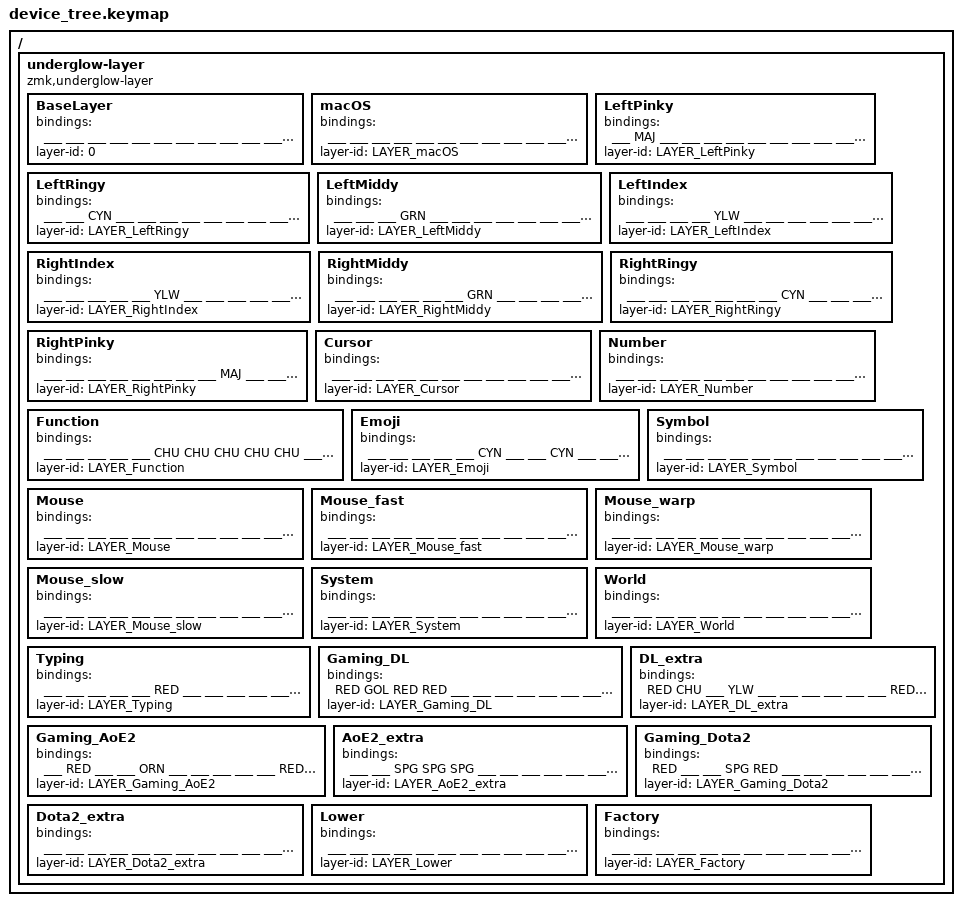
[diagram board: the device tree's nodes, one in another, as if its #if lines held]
//////////////////////////////////////////////////////////////////////////////
//
// Per-key RGB indicators for layers & mods -- requires PR36 beta firmware:
// override "EXPERIMENTAL_RGB_LAYER" to "y" in Advanced Configuration and
// select "community.pr36.per-key-rgb" from the drop-down menu located at
// Glove80 Layout Editor > Settings > Advanced Settings > Firmware Version
//
// - https://github.com/moergo-sc/zmk/pull/36
// - https://github.com/moergo-sc/zmk/pull/30
// - https://github.com/zmkfirmware/zmk/pull/2752
// - https://dev.glove80.com/#/layout/user/c42ac32d-dc0d-4160-9ee3-fd0fc15f1725
//
//////////////////////////////////////////////////////////////////////////////

#if __has_include(<dt-bindings/zmk/rgb_colors.h>)
  //
  // Color definitions with conflict guard to prevent
  // accidental redefinition of common abbreviations.
  //
  #if defined(RED) || defined(RED_RGB) || \
      defined(DOR) || defined(DOR_RGB) || \
      defined(COR) || defined(COR_RGB) || \
      defined(ORN) || defined(ORN_RGB) || \
      defined(GDN) || defined(GDN_RGB) || \
      defined(GOL) || defined(GOL_RGB) || \
      defined(YLW) || defined(YLW_RGB) || \
      defined(CHU) || defined(CHU_RGB) || \
      defined(GRN) || defined(GRN_RGB) || \
      defined(SPG) || defined(SPG_RGB) || \
      defined(CYN) || defined(CYN_RGB) || \
      defined(AZU) || defined(AZU_RGB) || \
      defined(TEA) || defined(TEA_RGB) || \
      defined(TUR) || defined(TUR_RGB) || \
      defined(BLU) || defined(BLU_RGB) || \
      defined(PUR) || defined(PUR_RGB) || \
      defined(MAJ) || defined(MAJ_RGB) || \
      defined(PNK) || defined(PNK_RGB) || \
      defined(WHT) || defined(WHT_RGB) || \
      defined(BLK) || defined(BLK_RGB) || \
      defined(___) || \
      defined(DUG) || defined(DUG_RGB) || \
      defined(LAC) || defined(LAC_RGB) || \
      defined(BSL) || defined(BNL) || defined(BCL) || \
      defined(SSL) || defined(SNL) || defined(SCL) || \
      defined(FST) || defined(WRP) || defined(SLO)
  #error "Naming conflict: 3-letter color abbreviation already defined!"
  #endif

  //
  // color definitions from QMK
  // https://github.com/qmk/qmk_firmware/blob/master/quantum/color.h
  //

  // used for delete & other possibly very destructive keys
  // also used to indicate which layer is currently active
  #define RED_RGB 0xFF0000 // #FF0000 RED      => RED (red)

  // used for keys that are not AS destructive, but whose function is to close/quit things.
  // also used for the escape characters `\` and ```
  #define DOR_RGB 0xFF4500 // #FF4500 DARKORN  => DOR (dark ornj)

  // used for basic, all rounder punctuations such as `;,.'"%:@`
  #define COR_RGB 0xFF7C4D // #FF7C4D CORAL    => COR (coral)

  // used for number keys
  // also used for ^$ vim start/end of line keys and for home/end
  #define ORN_RGB 0xFF8000 // #FF8000 ORANGE   => ORN (ornj)

  // used for /*+- and such keys that can represent some sort of "operation"
  #define GDN_RGB 0xD9A521 // #D9A521 GOLDNROD => GDN (gold'nrod)

  // used for !~#? keys, meant to often be combined with other symbols, their functionality
  // often ressembles that of the GDN_RGB keys: thus, so does their color.
  #define GOL_RGB 0xFFD900 // #FFD900 GOLD     => GOL (gold)

  // SHIFT HRM.
  // also used for sticky shift keys
  #define YLW_RGB 0xFFFF00 // #FFFF00 YELLOW   => YLW (yellow)

  //
  #define CHU_RGB 0x80FF00 // #80FF00 CHARTRSE => CHU (chartreuse)

  // CTRL HRM.
  #define GRN_RGB 0x00FF00 // #00FF00 GREEN    => GRN (green)

  //
  #define SPG_RGB 0x00FF80 // #00FF80 SPRINGRN => SPG (spring green)

  // ALT/OPT OS HMR.
  #define CYN_RGB 0x00FFFF // #00FFFF CYAN     => CYN (sigh-an)

  // used for simple keys that do not do much on their own, such as an ArrowKey,
  // a Mouse Direction key, or a simple letter, sometimes capitalized.
  #define AZU_RGB 0x99F5FF // #99F5FF AZURE    => AZU (a-zur)

  // sligth variation of AZU_RGB, for very similar keys
  #define TUR_RGB 0x476E6A // #476E6A TURQUOIS => TUR (turquoise)

  // used for "containers" keys: (), [], {}, <>
  #define TEA_RGB 0x008080 // #008080 TEAL     => TEA (teel)

  // used only for a few programming fundamental keys such as `_`, `|` and `&`
  #define BLU_RGB 0x0000FF // #0000FF BLUE     => BLU (bloo)

  // used for combo keys (undo, redo, <c-f> find), not quite real macros yet
  #define PUR_RGB 0x7A00FF // #7A00FF PURPLE   => PUR (purp)

  // OS KEY HRM.
  #define MAJ_RGB 0xFF00FF // #FF00FF MAGENTA  => MAJ (mah-jenta)

  // used for the `=` key
  #define PNK_RGB 0xFF80BF // #FF80BF PINK     => PNK (pink)

  // used for macro keys
  #define WHT_RGB 0xFFFFFF // #FFFFFF WHITE    => WHT (white)

  // no RBG lighting. Used for keys that shoud not require a particular effort remembering —
  // mostly, alpha layout keys
  #define BLK_RGB 0x000000 // #000000 BLACK    => BLK (blak)

  //
  // color definitions from MoErgo
  // https://github.com/moergo-sc/zmk/blob/aca523dfce9b6447ffd19d833b791d44f1f286de/app/src/rgb_underglow.c#L259-L265
  //
  #define DUG_RGB 0x00ff68 // #00ff68 DULL_GRN => DUG (dull green)

  // used for layer switching keys.
  // also used for the Space, Backspace, Tab and Enter keys on temporary layers
  #define LAC_RGB 0x6b1fce // #6b1fce LILAC    => LAC (lilac)

  //
  // underglow for the colors above
  //
  #define RED &ug RED_RGB
  #define DOR &ug DOR_RGB
  #define COR &ug COR_RGB
  #define ORN &ug ORN_RGB
  #define GDN &ug GDN_RGB
  #define GOL &ug GOL_RGB
  #define YLW &ug YLW_RGB
  #define CHU &ug CHU_RGB
  #define GRN &ug GRN_RGB
  #define SPG &ug SPG_RGB
  #define CYN &ug CYN_RGB
  #define AZU &ug AZU_RGB
  #define TEA &ug TEA_RGB
  #define TUR &ug TUR_RGB
  #define BLU &ug BLU_RGB
  #define PUR &ug PUR_RGB
  #define MAJ &ug MAJ_RGB
  #define PNK &ug PNK_RGB
  #define WHT &ug WHT_RGB
  #define BLK &ug BLK_RGB
  #define ___ &ug BLK_RGB
  #define DUG &ug DUG_RGB
  #define LAC &ug LAC_RGB

  //
  // underglow for keyboard locks on the Base layer
  //
  #define BSL &ug_sl BLK_RGB WHT_RGB // ScrollLock COLOR_OFF COLOR_ON
  #define BNL &ug_nl LAC_RGB WHT_RGB // NumLock    COLOR_OFF COLOR_ON
  #define BCL &ug_cl LAC_RGB WHT_RGB // CapsLock   COLOR_OFF COLOR_ON

  //
  // underglow for keyboard locks on the System layer
  //
  #define SSL &ug_sl BLK_RGB WHT_RGB // ScrollLock COLOR_OFF COLOR_ON
  #define SNL &ug_nl BLK_RGB WHT_RGB // NumLock    COLOR_OFF COLOR_ON
  #define SCL &ug_cl BLK_RGB WHT_RGB // CapsLock   COLOR_OFF COLOR_ON

  //
  // colors for mouse speed scaling in Mouse layers
  //
  #define FST GOL
  #define SLO PNK
  #define WRP CHU

  // ==== PER-KEY-RGB <section begins> ====
  / {
    underglow-layer {
      compatible  = "zmk,underglow-layer";

      /*
      Template {
        bindings = <
          ___ ___ ___ ___ ___                                             ___ ___ ___ ___ ___
          ___ ___ ___ ___ ___ ___                                     ___ ___ ___ ___ ___ ___
          ___ ___ ___ ___ ___ ___                                     ___ ___ ___ ___ ___ ___
          ___ ___ ___ ___ ___ ___                                     ___ ___ ___ ___ ___ ___
          ___ ___ ___ ___ ___ ___     ___ ___ ___     ___ ___ ___     ___ ___ ___ ___ ___ ___
          ___ ___ ___ ___ ___         ___ ___ ___     ___ ___ ___         ___ ___ ___ ___ ___
        >;
        layer-id = <LAYER_Template>;
      };
      */

      BaseLayer {
        bindings = <
          ___ ___ ___ ___ ___                                             ___ ___ ___ ___ ___
          ___ ___ ___ ___ ___ ___                                     ___ ___ ___ ___ ___ ___
          ___ ___ ___ ___ ___ ___                                     ___ ___ ___ ___ ___ ___
          ___ MAJ CYN GRN YLW ___                                     ___ YLW GRN CYN MAJ ___
          YLW ___ ___ ___ ___ ___     LAC ___ ___     ___ ___ LAC     ___ ___ ___ ___ ___ YLW
          RED ___ ___ ___ LAC         BCL BNL BSL     ___ LAC LAC         LAC ___ ___ ___ ___
        >;
        layer-id = <0>;
      };

      #ifdef LAYER_macOS
      macOS {
        bindings = <
          ___ ___ ___ ___ ___                                             ___ ___ ___ ___ ___
          ___ ___ ___ ___ ___ ___                                     ___ ___ ___ ___ ___ ___
          ___ ___ ___ ___ ___ ___                                     ___ ___ ___ ___ ___ ___
          ___ GRN CYN MAJ YLW ___                                     ___ YLW MAJ CYN GRN ___
          YLW ___ ___ ___ ___ ___     LAC RED ___     ___ ___ LAC     ___ ___ ___ ___ ___ YLW
          RED RED ___ ___ LAC         BCL BNL BSL     ___ LAC LAC         LAC ___ ___ RED RED
        >;
        layer-id = <LAYER_macOS>;
      };
      #endif

      #ifdef LAYER_LeftPinky
      LeftPinky {
        bindings = <
          ___ MAJ ___ ___ ___                                             ___ ___ ___ ___ ___
          ___ ___ ___ ___ ___ ___                                     ___ ___ ___ ___ ___ ___
          ___ ___ ___ ___ ___ ___                                     ___ ___ ___ ___ ___ ___
          ___ MAJ CYN GRN YLW ___                                     ___ YLW GRN CYN MAJ ___
          YLW ___ ___ ___ ___ ___     LAC COR ___     ___ COR LAC     ___ ___ ___ ___ ___ YLW
          ___ ___ ___ ___ LAC         BCL BNL BSL     ___ LAC LAC         LAC ___ ___ ___ ___
        >;
        layer-id = <LAYER_LeftPinky>;
      };
      #endif

      #ifdef LAYER_LeftRingy
      LeftRingy {
        bindings = <
          ___ ___ CYN ___ ___                                             ___ ___ ___ ___ ___
          ___ ___ ___ ___ ___ ___                                     ___ ___ ___ ___ ___ ___
          ___ ___ ___ ___ ___ ___                                     ___ ___ ___ ___ ___ ___
          ___ MAJ CYN GRN YLW ___                                     ___ YLW GRN CYN MAJ ___
          YLW ___ ___ ___ ___ ___     LAC COR ___     ___ COR LAC     ___ ___ ___ ___ ___ YLW
          ___ ___ ___ ___ LAC         BCL BNL BSL     ___ LAC LAC         LAC ___ ___ ___ ___
        >;
        layer-id = <LAYER_LeftRingy>;
      };
      #endif

      #ifdef LAYER_LeftMiddy
      LeftMiddy {
        bindings = <
          ___ ___ ___ GRN ___                                             ___ ___ ___ ___ ___
          ___ ___ ___ ___ ___ ___                                     ___ ___ ___ ___ ___ ___
          ___ ___ ___ ___ ___ ___                                     ___ ___ ___ ___ ___ ___
          ___ MAJ CYN GRN YLW ___                                     ___ YLW GRN CYN MAJ ___
          YLW ___ ___ ___ ___ ___     LAC COR ___     ___ COR LAC     ___ ___ ___ ___ ___ YLW
          ___ ___ ___ ___ LAC         BCL BNL BSL     ___ LAC LAC         LAC ___ ___ ___ ___
        >;
        layer-id = <LAYER_LeftMiddy>;
      };
      #endif

      #ifdef LAYER_LeftIndex
      LeftIndex {
        bindings = <
          ___ ___ ___ ___ YLW                                             ___ ___ ___ ___ ___
          ___ ___ ___ ___ ___ ___                                     ___ ___ ___ ___ ___ ___
          ___ ___ ___ ___ ___ ___                                     ___ ___ ___ ___ ___ ___
          ___ MAJ CYN GRN YLW ___                                     ___ YLW GRN CYN MAJ ___
          YLW ___ ___ ___ ___ ___     LAC COR ___     ___ COR LAC     ___ ___ ___ ___ ___ YLW
          ___ ___ ___ ___ LAC         BCL BNL BSL     ___ LAC LAC         LAC ___ ___ ___ ___
        >;
        layer-id = <LAYER_LeftIndex>;
      };
      #endif

      #ifdef LAYER_RightIndex
      RightIndex {
        bindings = <
          ___ ___ ___ ___ ___                                             YLW ___ ___ ___ ___
          ___ ___ ___ ___ ___ ___                                     ___ ___ ___ ___ ___ ___
          ___ ___ ___ ___ ___ ___                                     ___ ___ ___ ___ ___ ___
          ___ MAJ CYN GRN YLW ___                                     ___ YLW GRN CYN MAJ ___
          YLW ___ ___ ___ ___ ___     LAC COR ___     ___ COR LAC     ___ ___ ___ ___ ___ YLW
          ___ ___ ___ ___ LAC         BCL BNL BSL     ___ LAC LAC         LAC ___ ___ ___ ___
        >;
        layer-id = <LAYER_RightIndex>;
      };
      #endif

      #ifdef LAYER_RightMiddy
      RightMiddy {
        bindings = <
          ___ ___ ___ ___ ___                                             ___ GRN ___ ___ ___
          ___ ___ ___ ___ ___ ___                                     ___ ___ ___ ___ ___ ___
          ___ ___ ___ ___ ___ ___                                     ___ ___ ___ ___ ___ ___
          ___ MAJ CYN GRN YLW ___                                     ___ YLW GRN CYN MAJ ___
          YLW ___ ___ ___ ___ ___     LAC COR ___     ___ COR LAC     ___ ___ ___ ___ ___ YLW
          ___ ___ ___ ___ LAC         BCL BNL BSL     ___ LAC LAC         LAC ___ ___ ___ ___
        >;
        layer-id = <LAYER_RightMiddy>;
      };
      #endif

      #ifdef LAYER_RightRingy
      RightRingy {
        bindings = <
          ___ ___ ___ ___ ___                                             ___ ___ CYN ___ ___
          ___ ___ ___ ___ ___ ___                                     ___ ___ ___ ___ ___ ___
          ___ ___ ___ ___ ___ ___                                     ___ ___ ___ ___ ___ ___
          ___ MAJ CYN GRN YLW ___                                     ___ YLW GRN CYN MAJ ___
          YLW ___ ___ ___ ___ ___     LAC COR ___     ___ COR LAC     ___ ___ ___ ___ ___ YLW
          ___ ___ ___ ___ LAC         BCL BNL BSL     ___ LAC LAC         LAC ___ ___ ___ ___
        >;
        layer-id = <LAYER_RightRingy>;
      };
      #endif

      #ifdef LAYER_RightPinky
      RightPinky {
        bindings = <
          ___ ___ ___ ___ ___                                             ___ ___ ___ MAJ ___
          ___ ___ ___ ___ ___ ___                                     ___ ___ ___ ___ ___ ___
          ___ ___ ___ ___ ___ ___                                     ___ ___ ___ ___ ___ ___
          ___ MAJ CYN GRN YLW ___                                     ___ YLW GRN CYN MAJ ___
          YLW ___ ___ ___ ___ ___     LAC COR ___     ___ COR LAC     ___ ___ ___ ___ ___ YLW
          ___ ___ ___ ___ LAC         BCL BNL BSL     ___ LAC LAC         LAC ___ ___ ___ ___
        >;
        layer-id = <LAYER_RightPinky>;
      };
      #endif

      #ifdef LAYER_Cursor
      Cursor {
        bindings = <
          ___ ___ ___ ___ ___                                             ___ ___ ___ ___ ___
          ___ ___ ___ ___ ___ ___                                     ___ ___ ___ ___ ___ ___
          ___ ___ WHT WHT WHT GDN                                     ___ ___ COR COR DOR ___
          WHT MAJ CYN GRN YLW GDN                                     BLU AZU AZU AZU AZU ___
          WHT RED PUR PUR GDN GDN     ___ ___ ___     WHT WHT WHT     BLU ORN PUR PUR ORN ___
          WHT PNK PUR PUR PUR         RED ___ ___     WHT WHT WHT         ___ COR COR PNK ___
        >;
        layer-id = <LAYER_Cursor>;
      };
      #endif

      #ifdef LAYER_Number
      Number {
        bindings = <
          ___ ___ ___ ___ ___                                             ___ ___ ___ ___ ___
          ___ ___ ___ ___ ___ ___                                     ___ ___ ___ ___ ___ ___
          ___ PNK PNK PNK PNK PNK                                     TUR ORN ORN ORN BLU ___
          ___ MAJ CYN GRN YLW PNK                                     AZU ORN ORN ORN PNK AZU
          WHT COR COR COR COR PNK     ___ ___ ___     ___ LAC LAC     AZU ORN ORN ORN BLU ___
          ___ YLW PNK PNK PNK         ___ RED ___     LAC LAC ORN         ___ PNK PNK YLW ___
        >;
        layer-id = <LAYER_Number>;
      };
      #endif

      #ifdef LAYER_Function
      Function {
        bindings = <
          ___ ___ ___ ___ ___                                             CHU CHU CHU CHU CHU
          ___ ___ ___ ___ ___ ___                                     TEA ___ ___ ___ ___ ___
          ___ ___ ___ ___ ___ ___                                     TEA AZU AZU AZU AZU TEA
          ___ MAJ CYN GRN YLW ___                                     TEA AZU AZU AZU AZU TEA
          ___ ___ ___ ___ ___ ___     RED ___ ___     COR ORN BLU     TEA AZU AZU AZU AZU TEA
          ___ ___ ___ ___ ___         ___ ___ ___     COR CYN CYN         BLU BLU BLU BLU BLU
        >;
        layer-id = <LAYER_Function>;
      };
      #endif

      #ifdef LAYER_Emoji
      Emoji {
        bindings = <
          ___ ___ ___ ___ ___                                             CYN ___ ___ CYN ___
          ___ ___ ___ ___ ___ ___                                     ___ CYN ___ ___ CYN ___
          ___ ___ ___ ___ ___ ___                                     ___ ___ ___ ___ ___ ___
          ___ GDN PNK SPG AZU ___                                     CYN ___ ___ ___ ___ CYN
          ___ ___ ___ ___ ___ ___     ___ ___ ___     ___ ___ ___     ___ CYN ___ ___ CYN ___
          ___ ___ ___ ___ RED         YLW ___ ___     ___ ___ ___         ___ CYN CYN ___ ___
        >;
        layer-id = <LAYER_Emoji>;
      };
      #endif

      #ifdef LAYER_Symbol
      Symbol {
        bindings = <
          ___ ___ ___ ___ ___                                             ___ ___ ___ ___ ___
          ___ ___ TEA TEA ___ ___                                     ___ ___ ___ ___ ___ ___
          WHT TEA TEA TEA TEA GOL                                     ___ GOL GOL GOL ___ ___
          WHT ORN PNK BLU ORN GDN                                     COR YLW GRN CYN MAJ ___
          WHT TEA BLU GDN TEA GDN     DOR DOR ___     ___ ___ ___     COR DOR DOR COR ___ ___
          WHT BLU COR COR GDN         COR COR COR     ___ ___ RED         LAC LAC LAC LAC WHT
        >;
        layer-id = <LAYER_Symbol>;
      };
      #endif

      #ifdef LAYER_Mouse
      Mouse {
        bindings = <
          ___ ___ ___ ___ ___                                             ___ ___ ___ ___ ___
          ___ ___ ___ ___ ___ ___                                     ___ ___ ___ ___ ___ ___
          ___ ___ ___ ___ ___ ___                                     ___ ___ ___ ___ ___ ___
          ___ SPG SPG AZU SPG CYN                                     BLU YLW GRN CYN MAJ ___
          ___ SPG AZU AZU AZU CYN     TUR ___ COR     ___ ___ ___     BLU SLO FST WRP COR ___
          ___ ___ ___ ___ ___         AZU AZU COR     ___ RED ___         GDN GDN GDN ___ ___
        >;
        layer-id = <LAYER_Mouse>;
      };
      #endif

      #ifdef LAYER_Mouse_fast
      Mouse_fast {
        bindings = <
          ___ ___ ___ ___ ___                                             ___ ___ ___ ___ ___
          ___ ___ ___ ___ ___ ___                                     ___ ___ ___ ___ ___ ___
          ___ ___ ___ ___ ___ ___                                     ___ ___ ___ ___ ___ ___
          ___ SPG SPG FST SPG CYN                                     BLU YLW GRN CYN MAJ ___
          ___ SPG FST FST FST CYN     TUR ___ COR     ___ ___ ___     BLU FST FST FST COR ___
          ___ ___ ___ ___ ___         AZU AZU COR     ___ RED ___         GDN GDN GDN AZU ___
        >;
        layer-id = <LAYER_Mouse_fast>;
      };
      #endif

      #ifdef LAYER_Mouse_warp
      Mouse_warp {
        bindings = <
          ___ ___ ___ ___ ___                                             ___ ___ ___ ___ ___
          ___ ___ ___ ___ ___ ___                                     ___ ___ ___ ___ ___ ___
          ___ ___ ___ ___ ___ ___                                     ___ ___ ___ ___ ___ ___
          ___ SPG SPG WRP SPG CYN                                     BLU YLW GRN CYN MAJ ___
          ___ SPG WRP WRP WRP CYN     TUR ___ COR     ___ ___ ___     BLU WRP WRP WRP COR ___
          ___ ___ ___ ___ ___         AZU AZU COR     ___ RED ___         GDN GDN GDN AZU ___
        >;
        layer-id = <LAYER_Mouse_warp>;
      };
      #endif

      #ifdef LAYER_Mouse_slow
      Mouse_slow {
        bindings = <
          ___ ___ ___ ___ ___                                             ___ ___ ___ ___ ___
          ___ ___ ___ ___ ___ ___                                     ___ ___ ___ ___ ___ ___
          ___ ___ ___ ___ ___ ___                                     ___ ___ ___ ___ ___ ___
          ___ SPG SPG SLO SPG CYN                                     BLU YLW GRN CYN MAJ ___
          ___ SPG SLO SLO SLO CYN     TUR ___ COR     ___ ___ ___     BLU SLO SLO SLO COR ___
          ___ ___ ___ ___ ___         AZU AZU COR     ___ RED ___         GDN GDN GDN AZU ___
        >;
        layer-id = <LAYER_Mouse_slow>;
      };
      #endif

      #ifdef LAYER_System
      System {
        bindings = <
          ___ ___ ___ ___ ___                                             ___ ___ ___ ___ ___
          ___ ___ ___ ___ ___ ___                                     ___ ___ ___ ___ ___ ___
          ___ PNK AZU SPG GDN COR                                     ___ ___ ___ ___ ___ ___
          ___ PNK AZU SPG GDN COR                                     ___ YLW GRN CYN MAJ ___
          ___ ___ BLU BLU BLU COR     PUR PUR PUR     ___ ___ RED     ___ ___ ___ ___ ___ ___
          ___ ___ ___ ___ ORN         SCL SNL SSL     ___ ___ ___         ___ ___ ___ ___ ___
        >;
        layer-id = <LAYER_System>;
      };
      #endif

      #ifdef LAYER_World
      World {
        bindings = <
          ___ ___ ___ ___ ___                                             ___ ___ ___ ___ ___
          ___ ___ ___ ___ ___ ___                                     ___ ___ ___ ___ ___ ___
          ___ SPG AZU AZU AZU ___                                     ___ ___ CYN CYN ___ ___
          AZU AZU AZU AZU AZU ___                                     ___ YLW GRN GRN YLW ___
          AZU AZU SPG SPG AZU ___     ___ ___ ___     ___ ___ ___     ___ ___ ___ ___ ___ ___
          SPG SPG SPG SPG SPG         ___ ___ ___     ___ ___ RED         RED ___ ___ ___ ___
        >;
        layer-id = <LAYER_World>;
      };
      #endif

      #ifdef LAYER_Typing
      Typing {
        bindings = <
          ___ ___ ___ ___ ___                                             RED ___ ___ ___ ___
          ___ ___ ___ ___ ___ ___                                     RED ___ ___ ___ ___ ___
          ___ ___ ___ ___ ___ ___                                     ___ ___ ___ ___ ___ ___
          ___ ___ ___ ___ ___ ___                                     ___ ___ ___ ___ ___ ___
          ___ ___ ___ ___ ___ ___     ___ ___ ___     ___ ___ ___     ___ ___ ___ ___ ___ ___
          ___ ___ ___ ___ ___         ___ ___ ___     ___ ___ ___         ___ ___ ___ ___ ___
        >;
        layer-id = <LAYER_Typing>;
      };
      #endif

      #ifdef LAYER_Gaming_DL
      Gaming_DL {
        bindings = <
          RED GOL RED RED ___                                             ___ ___ ___ ___ ___
          ___ ___ ___ ___ ___ ___                                     ___ ___ ___ ___ ___ ___
          ___ ___ ORN ___ ___ RED                                     ___ ___ ___ ___ ___ ___
          ___ BLU MAJ ___ ORN ORN                                     ___ ___ ___ ___ ___ ___
          ___ WHT ___ ___ ___ BLU     CHU ___ ___     ___ ___ ___     ___ ___ ___ ___ ___ ___
          ___ BLU BLU MAJ BLU         WHT ___ MAJ     ___ ___ ___         ___ ___ ___ ___ ___
        >;
        layer-id = <LAYER_Gaming_DL>;
      };
      #endif

      #ifdef LAYER_DL_extra
      DL_extra {
        bindings = <
          RED CHU ___ YLW ___                                             ___ ___ ___ ___ ___
          RED ___ YLW YLW YLW ___                                     ___ ___ ___ ___ ___ ___
          RED WHT ___ ___ ___ WHT                                     ___ ___ ___ ___ ___ ___
          ___ ___ CYN ___ CYN CYN                                     ___ ___ ___ ___ ___ ___
          ___ WHT CYN ___ CYN ___     ___ ___ ___     ___ ___ ___     ___ ___ ___ ___ ___ ___
          ___ ___ ___ ___ ___         ___ ___ ___     ___ ___ ___         ___ ___ ___ ___ ___
        >;
        layer-id = <LAYER_DL_extra>;
      };
      #endif

      #ifdef LAYER_Gaming_AoE2
      Gaming_AoE2 {
        bindings = <
          ___ RED ___ ___ ORN                                             ___ ___ ___ ___ ___
          RED ___ ___ ___ ___ ___                                     ___ ___ ___ ___ ___ ___
          ___ COR COR COR COR COR                                     ___ ___ ___ ___ ___ ___
          ___ LAC LAC LAC LAC LAC                                     ___ ___ ___ ___ ___ ___
          LAC WHT ___ ___ ___ ___     TEA ___ TEA     ___ ___ ___     ___ ___ ___ ___ ___ ___
          LAC ___ ___ ___ ___         ___ ___ TEA     ___ ___ ___         ___ ___ ___ ___ ___
        >;
        layer-id = <LAYER_Gaming_AoE2>;
      };
      #endif

      #ifdef LAYER_AoE2_extra
      AoE2_extra {
        bindings = <
          ___ ___ SPG SPG SPG                                             ___ ___ ___ ___ ___
          ___ ___ PNK PNK PNK PNK                                     ___ ___ ___ ___ ___ ___
          ___ ___ ORN AZU ORN ___                                     ___ ___ ___ ___ ___ ___
          ___ AZU AZU AZU AZU AZU                                     ___ ___ ___ ___ ___ ___
          AZU WHT ___ ___ ___ ___     ___ ___ ___     ___ ___ ___     ___ ___ ___ ___ ___ ___
          AZU AZU ___ ___ ___         RED ___ ___     ___ ___ ___         ___ ___ ___ ___ ___
        >;
        layer-id = <LAYER_AoE2_extra>;
      };
      #endif

      #ifdef LAYER_Gaming_Dota2
      Gaming_Dota2 {
        bindings = <
          RED ___ ___ SPG RED                                             ___ ___ ___ ___ ___
          ___ ___ ___ ___ ___ RED                                     ___ ___ ___ ___ ___ ___
          ___ COR COR COR COR COR                                     ___ ___ ___ ___ ___ ___
          WHT ___ LAC LAC LAC LAC                                     ___ ___ ___ ___ ___ ___
          ORN BLU ___ ___ LAC LAC     ___ BLU ___     ___ ___ GRN     ___ ___ ___ ___ ___ ___
          CYN BLU BLU BLU BLU         ___ ___ ___     ___ ___ RED         ___ ___ ___ ___ ___
        >;
        layer-id = <LAYER_Gaming_Dota2>;
      };
      #endif

      #ifdef LAYER_Dota2_extra
      Dota2_extra {
        bindings = <
          ___ ___ ___ ___ ___                                             ___ ___ ___ ___ ___
          ___ ___ ___ ___ ___ ___                                     ___ ___ ___ ___ ___ ___
          ___ ___ ___ ___ ___ ___                                     ___ ___ ___ ___ ___ ___
          ___ ___ COR COR COR SPG                                     ___ ___ ___ ___ ___ ___
          ___ SPG ___ ___ ___ ___     ___ ___ ___     ___ ___ ___     ___ ___ ___ ___ ___ ___
          ___ WHT WHT COR COR         ___ RED ___     ___ ___ ___         ___ ___ ___ ___ ___
        >;
        layer-id = <LAYER_Dota2_extra>;
      };
      #endif

      #ifdef LAYER_Lower
      Lower {
        bindings = <
          ___ ___ ___ ___ ___                                             ___ ___ ___ ___ ___
          ___ ___ ___ ___ ___ ___                                     ___ ___ ___ ___ ___ ___
          ___ GOL GOL GOL GOL GOL                                     GOL GOL GOL GOL GOL ___
          ___ MAJ CYN GRN YLW SPG                                     SPG YLW GRN CYN MAJ ___
          ___ SPG SPG SPG SPG SPG     RED ___ BLU     BLU ___ RED     SPG PNK PNK SPG PNK ___
          ___ ___ ___ ___ RED         RED RED COR     COR RED RED         RED ___ ___ ___ ___
        >;
        layer-id = <LAYER_Lower>;
      };
      #endif

      #ifdef LAYER_Factory
      Factory {
        bindings = <
          ___ ___ ___ ___ ___                                             ___ ___ ___ ___ ___
          ___ ___ ___ ___ ___ ___                                     ___ ___ ___ ___ ___ ___
          ___ ___ ___ ___ ___ ___                                     ___ ___ ___ ___ ___ ___
          ___ ___ ___ ___ ___ ___                                     ___ ___ ___ ___ ___ ___
          ___ ___ ___ ___ ___ ___     ___ ___ RED     ___ ___ ___     ___ ___ ___ ___ ___ ___
          RED ___ ___ ___ ___         ___ ___ ___     ___ ___ ___         ___ ___ ___ ___ ___
        >;
        layer-id = <LAYER_Factory>;
      };
      #endif

    };
  };
  // ==== PER-KEY-RGB <section ends> =====

  #undef RED
  #undef RED_RGB
  #undef COR
  #undef COR_RGB
  #undef ORN
  #undef ORN_RGB
  #undef GDN
  #undef GDN_RGB
  #undef GOL
  #undef GOL_RGB
  #undef YLW
  #undef YLW_RGB
  #undef CHU
  #undef CHU_RGB
  #undef GRN
  #undef GRN_RGB
  #undef SPG
  #undef SPG_RGB
  #undef CYN
  #undef CYN_RGB
  #undef AZU
  #undef AZU_RGB
  #undef TEA
  #undef TEA_RGB
  #undef TUR
  #undef TUR_RGB
  #undef BLU
  #undef BLU_RGB
  #undef PUR
  #undef PUR_RGB
  #undef MAJ
  #undef MAJ_RGB
  #undef PNK
  #undef PNK_RGB
  #undef WHT
  #undef WHT_RGB
  #undef BLK
  #undef BLK_RGB
  #undef ___
  #undef DUG
  #undef DUG_RGB
  #undef LAC
  #undef LAC_RGB

  #undef BSL
  #undef BNL
  #undef BCL

  #undef SSL
  #undef SNL
  #undef SCL

  #undef FST
  #undef WRP
  #undef SLO
#endif

